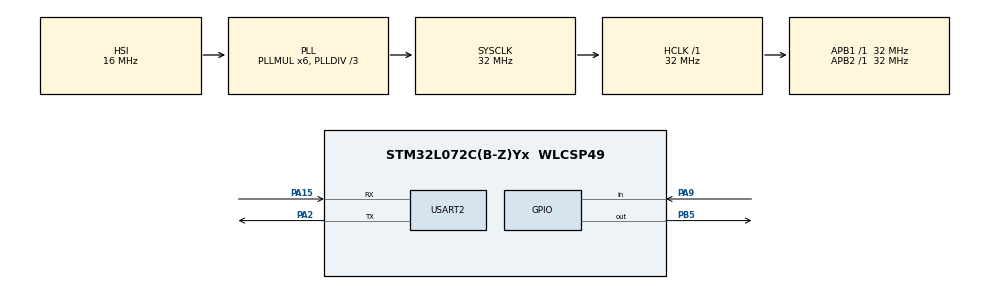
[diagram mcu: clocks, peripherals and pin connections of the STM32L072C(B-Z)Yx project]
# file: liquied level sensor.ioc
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Mcu.Family=STM32L0
Mcu.Name=STM32L072C(B-Z)Yx
Mcu.Package=WLCSP49
PA15.Mode=Asynchronous
PA15.Signal=USART2_RX
PA2.Mode=Asynchronous
PA2.Signal=USART2_TX
PA9.Signal=GPIO_Input
PB5.Signal=GPIO_Output
ProjectManager.HeapSize=0x200
ProjectManager.StackSize=0x400
ProjectManager.TargetToolchain=STM32CubeIDE
RCC.AHBFreq_Value=32000000
RCC.APB1Freq_Value=32000000
RCC.APB1TimFreq_Value=32000000
RCC.APB2Freq_Value=32000000
RCC.APB2TimFreq_Value=32000000
RCC.HCLKFreq_Value=32000000
RCC.HSE_VALUE=8000000
RCC.HSI16_VALUE=16000000
RCC.HSI48_VALUE=48000000
RCC.HSI_VALUE=16000000
RCC.LSE_VALUE=32768
RCC.MSI_VALUE=2097000
RCC.PLLDIV=RCC_PLLDIV_3
RCC.PLLMUL=RCC_PLLMUL_6
RCC.SYSCLKFreq_VALUE=32000000
RCC.SYSCLKSource=RCC_SYSCLKSOURCE_PLLCLK
RCC.VCOOutputFreq_Value=96000000
USART2.VirtualMode-Asynchronous=VM_ASYNC
board=B-L072Z-LRWAN1

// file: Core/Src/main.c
/* USER CODE BEGIN Header */
/**
  ******************************************************************************
  * @file           : main.c
  * @brief          : Main program body
  ******************************************************************************
  * @attention
  *
  * Copyright (c) 2024 STMicroelectronics.
  * All rights reserved.
  *
  * This software is licensed under terms that can be found in the LICENSE file
  * in the root directory of this software component.
  * If no LICENSE file comes with this software, it is provided AS-IS.
  *
  ******************************************************************************
  */
/* USER CODE END Header */
#include "main.h"
#include "stm32l0xx_hal.h"
#include "stm32l0xx_hal_def.h"
#include "stdio.h"

UART_HandleTypeDef huart2;

void SystemClock_Config(void);
void MX_GPIO_Init(void);
void MX_USART2_UART_Init(void);
void Error_Handler(void);
void SystemClock_Config(void);

int main(void)
{

  /* MCU Configuration--------------------------------------------------------*/

  /* Reset of all peripherals, Initializes the Flash interface and the Systick. */
  HAL_Init();

  /* Configure the system clock */
  SystemClock_Config();

  /* Initialize all configured peripherals */
  MX_GPIO_Init();
  MX_USART2_UART_Init();

  /* Infinite loop */
  while (1)
  {

    /* USER CODE BEGIN 3 */
	  uint8_t massage_High[] ="Water LEVEL is Stable\n\r";
	  uint8_t massage_LOW[] = "Water LEVEL is Danger\n\r";
	  if(HAL_GPIO_ReadPin(GPIOA, GPIO_PIN_9)== GPIO_PIN_RESET)
	  {

		  HAL_GPIO_WritePin(GPIOB, GPIO_PIN_5, GPIO_PIN_SET);
		  HAL_UART_Transmit(&huart2, massage_High, sizeof(massage_High), 1000);
          HAL_Delay(1000);
	  }
	  else
	  {
		  HAL_UART_Transmit(&huart2, massage_LOW, sizeof(massage_LOW), 1000);
		  HAL_GPIO_WritePin(GPIOB, GPIO_PIN_5, GPIO_PIN_RESET);
		  HAL_Delay(1000);
       }
  /* USER CODE END 3 */
}
}
void SystemClock_Config(void)
{
  RCC_OscInitTypeDef RCC_OscInitStruct = {0};
  RCC_ClkInitTypeDef RCC_ClkInitStruct = {0};
  RCC_PeriphCLKInitTypeDef PeriphClkInit = {0};

  /** Configure the main internal regulator output voltage
  */
  __HAL_PWR_VOLTAGESCALING_CONFIG(PWR_REGULATOR_VOLTAGE_SCALE1);

  /** Initializes the RCC Oscillators according to the specified parameters
  * in the RCC_OscInitTypeDef structure.
  */
  RCC_OscInitStruct.OscillatorType = RCC_OSCILLATORTYPE_HSI;
  RCC_OscInitStruct.HSIState = RCC_HSI_ON;
  RCC_OscInitStruct.HSICalibrationValue = RCC_HSICALIBRATION_DEFAULT;
  RCC_OscInitStruct.PLL.PLLState = RCC_PLL_ON;
  RCC_OscInitStruct.PLL.PLLSource = RCC_PLLSOURCE_HSI;
  RCC_OscInitStruct.PLL.PLLMUL = RCC_PLLMUL_6;
  RCC_OscInitStruct.PLL.PLLDIV = RCC_PLLDIV_3;
  if (HAL_RCC_OscConfig(&RCC_OscInitStruct) != HAL_OK)
  {
    Error_Handler();
  }

  /** Initializes the CPU, AHB and APB buses clocks
  */
  RCC_ClkInitStruct.ClockType = RCC_CLOCKTYPE_HCLK|RCC_CLOCKTYPE_SYSCLK
                              |RCC_CLOCKTYPE_PCLK1|RCC_CLOCKTYPE_PCLK2;
  RCC_ClkInitStruct.SYSCLKSource = RCC_SYSCLKSOURCE_PLLCLK;
  RCC_ClkInitStruct.AHBCLKDivider = RCC_SYSCLK_DIV1;
  RCC_ClkInitStruct.APB1CLKDivider = RCC_HCLK_DIV1;
  RCC_ClkInitStruct.APB2CLKDivider = RCC_HCLK_DIV1;

  if (HAL_RCC_ClockConfig(&RCC_ClkInitStruct, FLASH_LATENCY_1) != HAL_OK)
  {
    Error_Handler();
  }
  PeriphClkInit.PeriphClockSelection = RCC_PERIPHCLK_USART2;
  PeriphClkInit.Usart2ClockSelection = RCC_USART2CLKSOURCE_PCLK1;
  if (HAL_RCCEx_PeriphCLKConfig(&PeriphClkInit) != HAL_OK)
  {
    Error_Handler();
  }
}

void MX_USART2_UART_Init(void)
{

  huart2.Instance = USART2;
  huart2.Init.BaudRate = 115200;
  huart2.Init.WordLength = UART_WORDLENGTH_8B;
  huart2.Init.StopBits = UART_STOPBITS_1;
  huart2.Init.Parity = UART_PARITY_NONE;
  huart2.Init.Mode = UART_MODE_TX_RX;
  huart2.Init.HwFlowCtl = UART_HWCONTROL_NONE;
  huart2.Init.OverSampling = UART_OVERSAMPLING_16;
  huart2.Init.OneBitSampling = UART_ONE_BIT_SAMPLE_DISABLE;
  huart2.AdvancedInit.AdvFeatureInit = UART_ADVFEATURE_NO_INIT;
  if (HAL_UART_Init(&huart2) != HAL_OK)
  {
    Error_Handler();
  }

}

void MX_GPIO_Init(void)
{
  GPIO_InitTypeDef GPIO_InitStruct = {0};

  /* GPIO Ports Clock Enable */
  __HAL_RCC_GPIOA_CLK_ENABLE();
  __HAL_RCC_GPIOB_CLK_ENABLE();

  /*Configure GPIO pin Output Level */
  HAL_GPIO_WritePin(GPIOB, GPIO_PIN_5, GPIO_PIN_RESET);

  /*Configure GPIO pin : PB5 */
  GPIO_InitStruct.Pin = GPIO_PIN_5;
  GPIO_InitStruct.Mode = GPIO_MODE_OUTPUT_PP;
  GPIO_InitStruct.Pull = GPIO_NOPULL;
  GPIO_InitStruct.Speed = GPIO_SPEED_FREQ_LOW;
  HAL_GPIO_Init(GPIOB, &GPIO_InitStruct);

  /*Configure GPIO pin : PA9 */
  GPIO_InitStruct.Pin = GPIO_PIN_9;
  GPIO_InitStruct.Mode = GPIO_MODE_INPUT;
  GPIO_InitStruct.Pull = GPIO_NOPULL;
  HAL_GPIO_Init(GPIOA, &GPIO_InitStruct);

}

void Error_Handler(void)
{
  __disable_irq();
  while (1)
  {
  }
}
